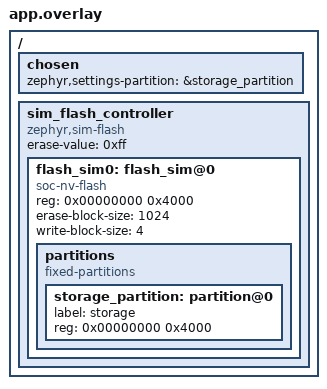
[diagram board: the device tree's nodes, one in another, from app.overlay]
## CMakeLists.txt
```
cmake_minimum_required(VERSION 3.20.0)
find_package(Zephyr REQUIRED HINTS $ENV{ZEPHYR_BASE})
project(settings_nvs)
# app.overlay (picked up automatically) adds a simulated flash with a storage partition
target_sources(app PRIVATE src/config.c src/test_settings.c)
```

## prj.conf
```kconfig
CONFIG_ZTEST=y
CONFIG_FLASH=y
CONFIG_FLASH_MAP=y
CONFIG_FLASH_SIMULATOR=y
CONFIG_NVS=y
CONFIG_SETTINGS=y
CONFIG_SETTINGS_NVS=y
CONFIG_SETTINGS_RUNTIME=y
```

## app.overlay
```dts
/* A RAM-backed flash (flash simulator) with one 16 KiB partition for settings/NVS, so the
 * example runs on qemu. On a real board drop this file: most board DTS files already have a
 * storage_partition in internal flash (BlackPill F411: sector 1, WeAct G431: last 8 KiB).
 */
/ {
	chosen {
		zephyr,settings-partition = &storage_partition;
	};

	sim_flash_controller: sim_flash_controller {
		compatible = "zephyr,sim-flash";
		#address-cells = <1>;
		#size-cells = <1>;
		erase-value = <0xff>;

		flash_sim0: flash_sim@0 {
			compatible = "soc-nv-flash";
			reg = <0x00000000 0x4000>;
			erase-block-size = <1024>;
			write-block-size = <4>;

			partitions {
				compatible = "fixed-partitions";
				#address-cells = <1>;
				#size-cells = <1>;

				storage_partition: partition@0 {
					label = "storage";
					reg = <0x00000000 0x4000>;
				};
			};
		};
	};
};
```

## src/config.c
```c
/* Settings handler for the "app" subtree: set() restores values on settings_load(), export()
 * writes them all (settings_save), commit() runs once a load is complete.
 */
#include <errno.h>
#include <string.h>
#include <zephyr/settings/settings.h>
#include "config.h"

struct app_config app_config;
int app_config_commits;

void app_config_defaults(void)
{
	memset(&app_config, 0, sizeof(app_config));
	strcpy(app_config.name, "unnamed");
	app_config.gain = 1;
}

static int set(const char *key, size_t len, settings_read_cb read_cb, void *cb_arg)
{
	const char *next;
	void *dst = NULL;
	size_t size = 0;

	if (settings_name_steq(key, "boot_count", &next) && !next) {
		dst = &app_config.boot_count; size = sizeof(app_config.boot_count);
	} else if (settings_name_steq(key, "name", &next) && !next) {
		dst = app_config.name; size = sizeof(app_config.name);
	} else if (settings_name_steq(key, "gain", &next) && !next) {
		dst = &app_config.gain; size = sizeof(app_config.gain);
	} else {
		return -ENOENT;
	}
	if (len > size) {
		return -EINVAL;
	}
	memset(dst, 0, size);
	return read_cb(cb_arg, dst, len) >= 0 ? 0 : -EIO;
}

static int get(const char *key, char *val, int val_len_max)
{
	const char *next;

	if (settings_name_steq(key, "gain", &next) && !next && val_len_max >= (int)sizeof(app_config.gain)) {
		memcpy(val, &app_config.gain, sizeof(app_config.gain));
		return sizeof(app_config.gain);
	}
	return -ENOENT;
}

static int commit(void)
{
	app_config_commits++;
	return 0;
}

static int export(int (*cb)(const char *name, const void *value, size_t val_len))
{
	cb("app/boot_count", &app_config.boot_count, sizeof(app_config.boot_count));
	cb("app/name", app_config.name, strlen(app_config.name) + 1);
	return cb("app/gain", &app_config.gain, sizeof(app_config.gain));
}

SETTINGS_STATIC_HANDLER_DEFINE(app, "app", get, set, commit, export);

int app_config_save(void)
{
	return settings_save();
}
```

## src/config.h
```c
#ifndef CONFIG_H_
#define CONFIG_H_
#include <stdint.h>

/* the app's persistent configuration: "app/boot_count", "app/name", "app/gain" */
struct app_config {
	uint32_t boot_count;
	char name[16];
	int16_t gain;
};

extern struct app_config app_config;
extern int app_config_commits;

void app_config_defaults(void);
int app_config_save(void);

#endif
```

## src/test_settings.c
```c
#include <string.h>
#include <zephyr/ztest.h>
#include <zephyr/settings/settings.h>
#include <zephyr/storage/flash_map.h>
#include "config.h"

static void *setup(void)
{
	const struct flash_area *fa;

	/* start from an erased partition, then mount the NVS backend */
	zassert_ok(flash_area_open(PARTITION_ID(storage_partition), &fa));
	zassert_ok(flash_area_erase(fa, 0, fa->fa_size));
	flash_area_close(fa);
	zassert_ok(settings_subsys_init());
	return NULL;
}

static void before(void *f)
{
	ARG_UNUSED(f);
	app_config_defaults();
	app_config_commits = 0;
}

ZTEST_SUITE(settings_nvs, NULL, setup, before, NULL, NULL);

ZTEST(settings_nvs, test_save_one_and_load)
{
	uint32_t count = 41;

	zassert_ok(settings_save_one("app/boot_count", &count, sizeof(count)));
	app_config_defaults();
	zassert_ok(settings_load());
	zassert_equal(app_config.boot_count, 41);
	zassert_true(app_config_commits >= 1, "commit() not called");
}

ZTEST(settings_nvs, test_export_all_then_reload)
{
	app_config.boot_count = 7;
	strcpy(app_config.name, "rov-1");
	app_config.gain = -3;
	zassert_ok(app_config_save());

	app_config_defaults(); /* as after a reset */
	zassert_ok(settings_load_subtree("app"));
	zassert_equal(app_config.boot_count, 7);
	zassert_str_equal(app_config.name, "rov-1");
	zassert_equal(app_config.gain, -3);
}

ZTEST(settings_nvs, test_newest_value_wins)
{
	for (uint32_t v = 100; v < 110; v++) {
		zassert_ok(settings_save_one("app/boot_count", &v, sizeof(v)));
	}
	app_config_defaults();
	zassert_ok(settings_load());
	zassert_equal(app_config.boot_count, 109);
}

ZTEST(settings_nvs, test_delete)
{
	const char name[] = "temp";

	zassert_ok(settings_save_one("app/name", name, sizeof(name)));
	zassert_ok(settings_delete("app/name"));
	app_config_defaults();
	zassert_ok(settings_load());
	zassert_str_equal(app_config.name, "unnamed", "deleted key must not come back");
}

ZTEST(settings_nvs, test_runtime_get_set)
{
	int16_t gain = 12, back = 0;

	/* runtime API: calls the handler's set()/get() directly, nothing is written to flash */
	zassert_ok(settings_runtime_set("app/gain", &gain, sizeof(gain)));
	zassert_equal(app_config.gain, 12);
	zassert_equal(settings_runtime_get("app/gain", &back, sizeof(back)), sizeof(back));
	zassert_equal(back, 12);
}

ZTEST(settings_nvs, test_many_writes_force_garbage_collection)
{
	/* 16 KiB / 1 KiB sectors: ~600 records of 24 bytes fill several sectors, NVS must recycle them */
	for (uint32_t v = 0; v < 600; v++) {
		zassert_ok(settings_save_one("app/boot_count", &v, sizeof(v)), "write %u", v);
	}
	app_config_defaults();
	zassert_ok(settings_load());
	zassert_equal(app_config.boot_count, 599);
}
```
